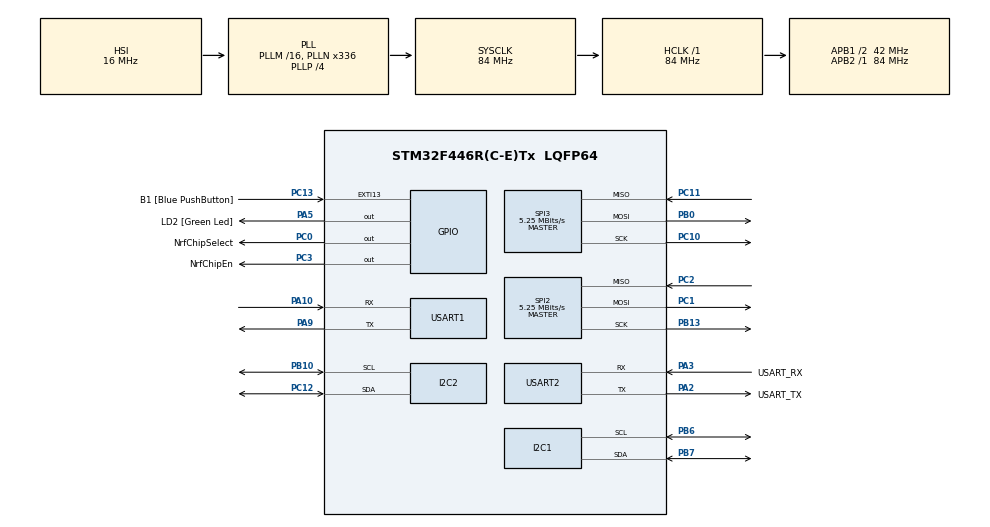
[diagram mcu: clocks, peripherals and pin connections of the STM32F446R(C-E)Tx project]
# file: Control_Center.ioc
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Dma.I2C1_RX.2.Direction=DMA_PERIPH_TO_MEMORY
Dma.I2C1_RX.2.FIFOMode=DMA_FIFOMODE_DISABLE
Dma.I2C1_RX.2.Instance=DMA1_Stream5
Dma.I2C1_RX.2.MemDataAlignment=DMA_MDATAALIGN_BYTE
Dma.I2C1_RX.2.MemInc=DMA_MINC_ENABLE
Dma.I2C1_RX.2.Mode=DMA_NORMAL
Dma.I2C1_RX.2.PeriphDataAlignment=DMA_PDATAALIGN_BYTE
Dma.I2C1_RX.2.PeriphInc=DMA_PINC_DISABLE
Dma.I2C1_RX.2.Priority=DMA_PRIORITY_LOW
Dma.I2C1_TX.3.Direction=DMA_MEMORY_TO_PERIPH
Dma.I2C1_TX.3.FIFOMode=DMA_FIFOMODE_DISABLE
Dma.I2C1_TX.3.Instance=DMA1_Stream6
Dma.I2C1_TX.3.MemDataAlignment=DMA_MDATAALIGN_BYTE
Dma.I2C1_TX.3.MemInc=DMA_MINC_ENABLE
Dma.I2C1_TX.3.Mode=DMA_NORMAL
Dma.I2C1_TX.3.PeriphDataAlignment=DMA_PDATAALIGN_BYTE
Dma.I2C1_TX.3.PeriphInc=DMA_PINC_DISABLE
Dma.I2C1_TX.3.Priority=DMA_PRIORITY_LOW
Dma.I2C2_RX.4.Direction=DMA_PERIPH_TO_MEMORY
Dma.I2C2_RX.4.FIFOMode=DMA_FIFOMODE_DISABLE
Dma.I2C2_RX.4.Instance=DMA1_Stream2
Dma.I2C2_RX.4.MemDataAlignment=DMA_MDATAALIGN_BYTE
Dma.I2C2_RX.4.MemInc=DMA_MINC_ENABLE
Dma.I2C2_RX.4.Mode=DMA_NORMAL
Dma.I2C2_RX.4.PeriphDataAlignment=DMA_PDATAALIGN_BYTE
Dma.I2C2_RX.4.PeriphInc=DMA_PINC_DISABLE
Dma.I2C2_RX.4.Priority=DMA_PRIORITY_LOW
Dma.I2C2_TX.5.Direction=DMA_MEMORY_TO_PERIPH
Dma.I2C2_TX.5.FIFOMode=DMA_FIFOMODE_DISABLE
Dma.I2C2_TX.5.Instance=DMA1_Stream7
Dma.I2C2_TX.5.MemDataAlignment=DMA_MDATAALIGN_BYTE
Dma.I2C2_TX.5.MemInc=DMA_MINC_ENABLE
Dma.I2C2_TX.5.Mode=DMA_NORMAL
Dma.I2C2_TX.5.PeriphDataAlignment=DMA_PDATAALIGN_BYTE
Dma.I2C2_TX.5.PeriphInc=DMA_PINC_DISABLE
Dma.I2C2_TX.5.Priority=DMA_PRIORITY_LOW
Dma.Request0=SPI2_RX
Dma.Request1=SPI2_TX
Dma.Request2=I2C1_RX
Dma.Request3=I2C1_TX
Dma.Request4=I2C2_RX
Dma.Request5=I2C2_TX
Dma.SPI2_RX.0.Direction=DMA_PERIPH_TO_MEMORY
Dma.SPI2_RX.0.FIFOMode=DMA_FIFOMODE_DISABLE
Dma.SPI2_RX.0.Instance=DMA1_Stream3
Dma.SPI2_RX.0.MemDataAlignment=DMA_MDATAALIGN_BYTE
Dma.SPI2_RX.0.MemInc=DMA_MINC_ENABLE
Dma.SPI2_RX.0.Mode=DMA_NORMAL
Dma.SPI2_RX.0.PeriphDataAlignment=DMA_PDATAALIGN_BYTE
Dma.SPI2_RX.0.PeriphInc=DMA_PINC_DISABLE
Dma.SPI2_RX.0.Priority=DMA_PRIORITY_LOW
Dma.SPI2_TX.1.Direction=DMA_MEMORY_TO_PERIPH
Dma.SPI2_TX.1.FIFOMode=DMA_FIFOMODE_DISABLE
Dma.SPI2_TX.1.Instance=DMA1_Stream4
Dma.SPI2_TX.1.MemDataAlignment=DMA_MDATAALIGN_BYTE
Dma.SPI2_TX.1.MemInc=DMA_MINC_ENABLE
Dma.SPI2_TX.1.Mode=DMA_NORMAL
Dma.SPI2_TX.1.PeriphDataAlignment=DMA_PDATAALIGN_BYTE
Dma.SPI2_TX.1.PeriphInc=DMA_PINC_DISABLE
Dma.SPI2_TX.1.Priority=DMA_PRIORITY_LOW
Mcu.Family=STM32F4
Mcu.Name=STM32F446R(C-E)Tx
Mcu.Package=LQFP64
NVIC.DMA1_Stream2_IRQn=true\:0\:0\:false\:false\:true\:false\:true\:true
NVIC.DMA1_Stream3_IRQn=true\:0\:0\:false\:false\:true\:false\:true\:true
NVIC.DMA1_Stream4_IRQn=true\:0\:0\:false\:false\:true\:false\:true\:true
NVIC.DMA1_Stream5_IRQn=true\:0\:0\:false\:false\:true\:false\:true\:true
NVIC.DMA1_Stream6_IRQn=true\:0\:0\:false\:false\:true\:false\:true\:true
NVIC.DMA1_Stream7_IRQn=true\:0\:0\:false\:false\:true\:false\:true\:true
NVIC.I2C1_EV_IRQn=true\:0\:0\:false\:false\:true\:true\:true\:true
NVIC.I2C2_EV_IRQn=true\:0\:0\:false\:false\:true\:true\:true\:true
NVIC.PriorityGroup=NVIC_PRIORITYGROUP_0
NVIC.SPI2_IRQn=true\:0\:0\:false\:false\:true\:true\:true\:true
NVIC.SPI3_IRQn=true\:0\:0\:false\:false\:true\:true\:true\:true
NVIC.USART1_IRQn=true\:0\:0\:false\:false\:true\:true\:true\:true
PA10.Mode=Asynchronous
PA10.Signal=USART1_RX
PA13.GPIO_Label=TMS
PA13.Mode=Serial_Wire
PA13.Signal=SYS_JTMS-SWDIO
PA14.GPIO_Label=TCK
PA14.Mode=Serial_Wire
PA14.Signal=SYS_JTCK-SWCLK
PA2.GPIO_Label=USART_TX
PA2.Mode=Asynchronous
PA2.Signal=USART2_TX
PA3.GPIO_Label=USART_RX
PA3.Mode=Asynchronous
PA3.Signal=USART2_RX
PA5.GPIO_Label=LD2 [Green Led]
PA5.Signal=GPIO_Output
PA9.Mode=Asynchronous
PA9.Signal=USART1_TX
PB0.Mode=Full_Duplex_Master
PB0.Signal=SPI3_MOSI
PB10.Mode=I2C
PB10.Signal=I2C2_SCL
PB13.Mode=Full_Duplex_Master
PB13.Signal=SPI2_SCK
PB3.GPIO_Label=SWO
PB3.Signal=SYS_JTDO-SWO
PB6.Mode=I2C
PB6.Signal=I2C1_SCL
PB7.Mode=I2C
PB7.Signal=I2C1_SDA
PC0.GPIO_Label=NrfChipSelect
PC0.Signal=GPIO_Output
PC1.Mode=Full_Duplex_Master
PC1.Signal=SPI2_MOSI
PC10.Mode=Full_Duplex_Master
PC10.Signal=SPI3_SCK
PC11.Mode=Full_Duplex_Master
PC11.Signal=SPI3_MISO
PC12.Mode=I2C
PC12.Signal=I2C2_SDA
PC13.GPIO_Label=B1 [Blue PushButton]
PC13.GPIO_ModeDefaultEXTI=GPIO_MODE_IT_FALLING
PC13.Signal=GPXTI13
PC14-OSC32_IN.Mode=LSE-External-Oscillator
PC14-OSC32_IN.Signal=RCC_OSC32_IN
PC15-OSC32_OUT.Mode=LSE-External-Oscillator
PC15-OSC32_OUT.Signal=RCC_OSC32_OUT
PC2.Mode=Full_Duplex_Master
PC2.Signal=SPI2_MISO
PC3.GPIO_Label=NrfChipEn
PC3.Signal=GPIO_Output
PH0-OSC_IN.Mode=HSE-External-Oscillator
PH0-OSC_IN.Signal=RCC_OSC_IN
PH1-OSC_OUT.Mode=HSE-External-Oscillator
PH1-OSC_OUT.Signal=RCC_OSC_OUT
ProjectManager.HeapSize=0x200
ProjectManager.StackSize=0x400
ProjectManager.TargetToolchain=STM32CubeIDE
RCC.48MHZClocksFreq_Value=84000000
RCC.AHBFreq_Value=84000000
RCC.APB1CLKDivider=RCC_HCLK_DIV2
RCC.APB1Freq_Value=42000000
RCC.APB1TimFreq_Value=84000000
RCC.APB2Freq_Value=84000000
RCC.APB2TimFreq_Value=84000000
RCC.CortexFreq_Value=84000000
RCC.FLatency-AdvancedSettings=FLASH_LATENCY_2
RCC.HCLKFreq_Value=84000000
RCC.HSE_VALUE=8000000
RCC.HSI_VALUE=16000000
RCC.PLLN=336
RCC.PLLP=RCC_PLLP_DIV4
RCC.SYSCLKFreq_VALUE=84000000
RCC.SYSCLKSource=RCC_SYSCLKSOURCE_PLLCLK
RCC.USBFreq_Value=168000000
RCC.VCOOutputFreq_Value=336000000
SPI2.BaudRatePrescaler=SPI_BAUDRATEPRESCALER_8
SPI2.CalculateBaudRate=5.25 MBits/s
SPI2.Direction=SPI_DIRECTION_2LINES
SPI2.Mode=SPI_MODE_MASTER
SPI2.VirtualType=VM_MASTER
SPI3.BaudRatePrescaler=SPI_BAUDRATEPRESCALER_8
SPI3.CalculateBaudRate=5.25 MBits/s
SPI3.Direction=SPI_DIRECTION_2LINES
SPI3.Mode=SPI_MODE_MASTER
SPI3.VirtualType=VM_MASTER
USART1.VirtualMode=VM_ASYNC
USART2.VirtualMode=VM_ASYNC
board=NUCLEO-F446RE

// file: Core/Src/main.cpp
/* USER CODE BEGIN Header */
/**
  ******************************************************************************
  * @file           : main.c
  * @brief          : Main program body
  ******************************************************************************
  * @attention
  *
  * Copyright (c) 2025 STMicroelectronics.
  * All rights reserved.
  *
  * This software is licensed under terms that can be found in the LICENSE file
  * in the root directory of this software component.
  * If no LICENSE file comes with this software, it is provided AS-IS.
  *
  ******************************************************************************
  */
/* USER CODE END Header */
#include "main.h"
#include "dma.h"
#include "i2c.h"
#include "spi.h"
#include "usart.h"
#include "gpio.h"
/* USER CODE BEGIN Includes */
#include <Lcd.h>
#include "Nrf2401Plus.h"
#include <SensorsData.h>
#include <Rtc.h>
/* USER CODE END Includes */

void SystemClock_Config(void);

int main(void)
{

  /* MCU Configuration--------------------------------------------------------*/

  /* Reset of all peripherals, Initializes the Flash interface and the Systick. */
  HAL_Init();

  /* Configure the system clock */
  SystemClock_Config();

  /* Initialize all configured peripherals */
  MX_GPIO_Init();
  MX_DMA_Init();
  MX_USART2_UART_Init();
  MX_SPI2_Init();
  MX_I2C1_Init();
  MX_I2C2_Init();
  MX_SPI3_Init();
  MX_USART1_UART_Init();
  /* USER CODE BEGIN 2 */
  	mLcd.Init();
  	Rtc.Init();
	NrfInit(RX, NrfChipEn_GPIO_Port,NrfChipEn_Pin,NrfChipSelect_GPIO_Port,NrfChipSelect_Pin,&hspi2);

  /* USER CODE END 2 */

  /* Infinite loop */
  while (1)
  {
	  // mLcd.Example();
	  NrfDataReceiving();
	  Rtc.GetDate();
	  SensorsData.ShowAllData();
  }
}

void SystemClock_Config(void)
{
  RCC_OscInitTypeDef RCC_OscInitStruct = {0};
  RCC_ClkInitTypeDef RCC_ClkInitStruct = {0};

  /** Configure the main internal regulator output voltage
  */
  __HAL_RCC_PWR_CLK_ENABLE();
  __HAL_PWR_VOLTAGESCALING_CONFIG(PWR_REGULATOR_VOLTAGE_SCALE3);

  /** Initializes the RCC Oscillators according to the specified parameters
  * in the RCC_OscInitTypeDef structure.
  */
  RCC_OscInitStruct.OscillatorType = RCC_OSCILLATORTYPE_HSI;
  RCC_OscInitStruct.HSIState = RCC_HSI_ON;
  RCC_OscInitStruct.HSICalibrationValue = RCC_HSICALIBRATION_DEFAULT;
  RCC_OscInitStruct.PLL.PLLState = RCC_PLL_ON;
  RCC_OscInitStruct.PLL.PLLSource = RCC_PLLSOURCE_HSI;
  RCC_OscInitStruct.PLL.PLLM = 16;
  RCC_OscInitStruct.PLL.PLLN = 336;
  RCC_OscInitStruct.PLL.PLLP = RCC_PLLP_DIV4;
  RCC_OscInitStruct.PLL.PLLQ = 2;
  RCC_OscInitStruct.PLL.PLLR = 2;
  if (HAL_RCC_OscConfig(&RCC_OscInitStruct) != HAL_OK)
  {
    Error_Handler();
  }

  /** Initializes the CPU, AHB and APB buses clocks
  */
  RCC_ClkInitStruct.ClockType = RCC_CLOCKTYPE_HCLK|RCC_CLOCKTYPE_SYSCLK
                              |RCC_CLOCKTYPE_PCLK1|RCC_CLOCKTYPE_PCLK2;
  RCC_ClkInitStruct.SYSCLKSource = RCC_SYSCLKSOURCE_PLLCLK;
  RCC_ClkInitStruct.AHBCLKDivider = RCC_SYSCLK_DIV1;
  RCC_ClkInitStruct.APB1CLKDivider = RCC_HCLK_DIV2;
  RCC_ClkInitStruct.APB2CLKDivider = RCC_HCLK_DIV1;

  if (HAL_RCC_ClockConfig(&RCC_ClkInitStruct, FLASH_LATENCY_2) != HAL_OK)
  {
    Error_Handler();
  }
}

void Error_Handler(void)
{
  __disable_irq();
  while (1)
  {
  }
}
